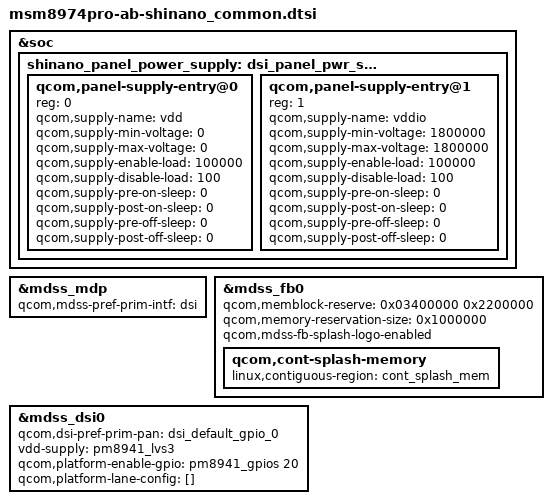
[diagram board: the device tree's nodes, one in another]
/* arch/arm/boot/dts/qcom/msm8974pro-ab-shinano_common.dtsi
 *
 * Copyright (C) 2014 Sony Mobile Communications Inc.
 *
 * This program is free software; you can redistribute it and/or modify
 * it under the terms of the GNU General Public License version 2 and
 * only version 2 as published by the Free Software Foundation.
 *
 * This program is distributed in the hope that it will be useful,
 * but WITHOUT ANY WARRANTY; without even the implied warranty of
 * MERCHANTABILITY or FITNESS FOR A PARTICULAR PURPOSE.  See the
 * GNU General Public License for more details.
 */

&soc {
	shinano_panel_power_supply: dsi_panel_pwr_supply {
		#address-cells = <1>;
		#size-cells = <0>;

		qcom,panel-supply-entry@0 {
			reg = <0>;
			qcom,supply-name = "vdd";
			qcom,supply-min-voltage = <0>;
			qcom,supply-max-voltage = <0>;
			qcom,supply-enable-load = <100000>;
			qcom,supply-disable-load = <100>;
			qcom,supply-pre-on-sleep = <0>;
			qcom,supply-post-on-sleep = <0>;
			qcom,supply-pre-off-sleep = <0>;
			qcom,supply-post-off-sleep = <0>;
		};

		qcom,panel-supply-entry@1 {
			reg = <1>;
			qcom,supply-name = "vddio";
			qcom,supply-min-voltage = <1800000>;
			qcom,supply-max-voltage = <1800000>;
			qcom,supply-enable-load = <100000>;
			qcom,supply-disable-load = <100>;
			qcom,supply-pre-on-sleep = <0>;
			qcom,supply-post-on-sleep = <0>;
			qcom,supply-pre-off-sleep = <0>;
			qcom,supply-post-off-sleep = <0>;
		};
	};
};

&mdss_mdp {
	qcom,mdss-pref-prim-intf = "dsi";
};

&mdss_fb0 {
	qcom,memblock-reserve = <0x03400000 0x2200000>;
	qcom,memory-reservation-size = <0x1000000>; /* size 16MB */
	qcom,mdss-fb-splash-logo-enabled;
	qcom,cont-splash-memory {
		linux,contiguous-region = <&cont_splash_mem>;
	};
};

&mdss_dsi0 {
	qcom,dsi-pref-prim-pan = <&dsi_default_gpio_0>;
	vdd-supply = <&pm8941_lvs3>;
	qcom,platform-enable-gpio = <&pm8941_gpios 20 0>;
	qcom,platform-lane-config = [];
};
